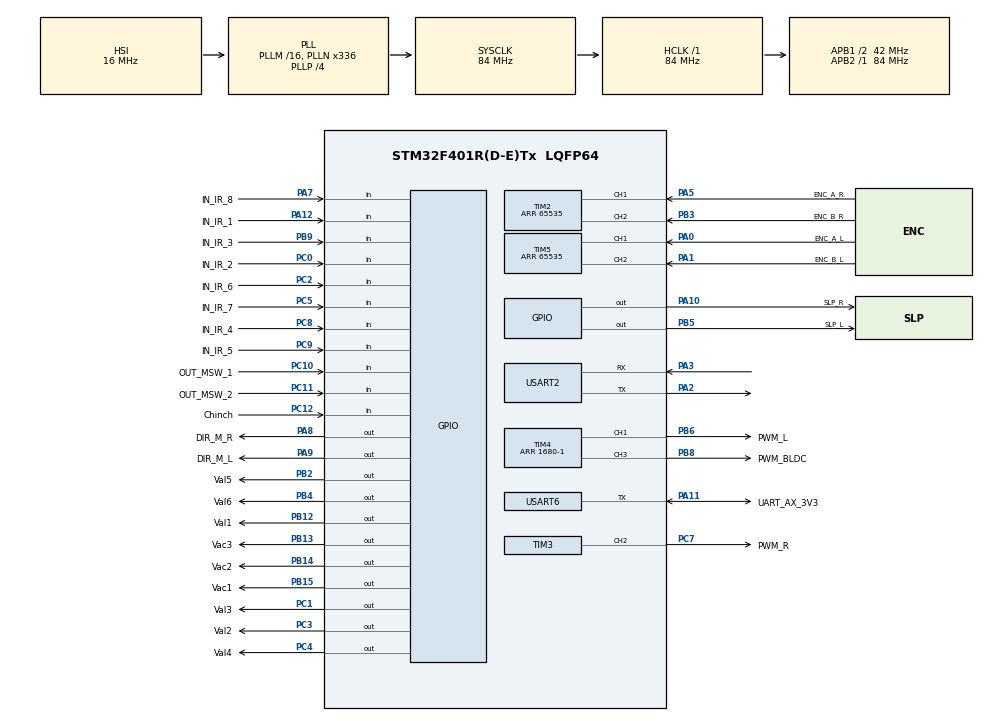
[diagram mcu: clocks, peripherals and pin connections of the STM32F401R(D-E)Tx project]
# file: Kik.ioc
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Mcu.Family=STM32F4
Mcu.Name=STM32F401R(D-E)Tx
Mcu.Package=LQFP64
NVIC.PriorityGroup=NVIC_PRIORITYGROUP_4
NVIC.TIM1_UP_TIM10_IRQn=true\:0\:0\:false\:false\:true\:true\:true\:true
PA0-WKUP.GPIO_Label=ENC_A_L
PA0-WKUP.Signal=S_TIM5_CH1
PA1.GPIO_Label=ENC_B_L
PA1.Signal=S_TIM5_CH2
PA10.GPIO_Label=SLP_R
PA10.PinState=GPIO_PIN_SET
PA10.Signal=GPIO_Output
PA11.GPIO_Label=UART_AX_3V3
PA11.GPIO_PuPd=GPIO_PULLUP
PA11.Mode=Half_duplex(single_wire_mode)
PA11.Signal=USART6_TX
PA12.GPIO_Label=IN_IR_1
PA12.Signal=GPIO_Input
PA2.Mode=Asynchronous
PA2.Signal=USART2_TX
PA3.Mode=Asynchronous
PA3.Signal=USART2_RX
PA5.GPIO_Label=ENC_A_R
PA5.Signal=S_TIM2_CH1_ETR
PA7.GPIO_Label=IN_IR_8
PA7.Signal=GPIO_Input
PA8.GPIO_Label=DIR_M_R
PA8.Signal=GPIO_Output
PA9.GPIO_Label=DIR_M_L
PA9.Signal=GPIO_Output
PB12.GPIO_Label=Val1
PB12.Signal=GPIO_Output
PB13.GPIO_Label=Vac3
PB13.Signal=GPIO_Output
PB14.GPIO_Label=Vac2
PB14.Signal=GPIO_Output
PB15.GPIO_Label=Vac1
PB15.Signal=GPIO_Output
PB2.GPIO_Label=Val5
PB2.Signal=GPIO_Output
PB3.GPIO_Label=ENC_B_R
PB3.Signal=S_TIM2_CH2
PB4.GPIO_Label=Val6
PB4.Signal=GPIO_Output
PB5.GPIO_Label=SLP_L
PB5.PinState=GPIO_PIN_SET
PB5.Signal=GPIO_Output
PB6.GPIO_Label=PWM_L
PB6.Signal=S_TIM4_CH1
PB8.GPIO_Label=PWM_BLDC
PB8.Signal=S_TIM4_CH3
PB9.GPIO_Label=IN_IR_3
PB9.Signal=GPIO_Input
PC0.GPIO_Label=IN_IR_2
PC0.Signal=GPIO_Input
PC1.GPIO_Label=Val3
PC1.Signal=GPIO_Output
PC10.GPIO_Label=OUT_MSW_1
PC10.Signal=GPIO_Input
PC11.GPIO_Label=OUT_MSW_2
PC11.Signal=GPIO_Input
PC12.GPIO_Label=Chinch
PC12.GPIO_PuPd=GPIO_PULLDOWN
PC12.Signal=GPIO_Input
PC2.GPIO_Label=IN_IR_6
PC2.Signal=GPIO_Input
PC3.GPIO_Label=Val2
PC3.Signal=GPIO_Output
PC4.GPIO_Label=Val4
PC4.Signal=GPIO_Output
PC5.GPIO_Label=IN_IR_7
PC5.Signal=GPIO_Input
PC7.GPIO_Label=PWM_R
PC7.Signal=S_TIM3_CH2
PC8.GPIO_Label=IN_IR_4
PC8.Signal=GPIO_Input
PC9.GPIO_Label=IN_IR_5
PC9.Signal=GPIO_Input
ProjectManager.HeapSize=0x200
ProjectManager.StackSize=0x400
ProjectManager.TargetToolchain=STM32CubeIDE
RCC.48MHZClocksFreq_Value=48000000
RCC.AHBFreq_Value=84000000
RCC.APB1CLKDivider=RCC_HCLK_DIV2
RCC.APB1Freq_Value=42000000
RCC.APB1TimFreq_Value=84000000
RCC.APB2Freq_Value=84000000
RCC.APB2TimFreq_Value=84000000
RCC.CortexFreq_Value=84000000
RCC.HCLKFreq_Value=84000000
RCC.HSE_VALUE=8000000
RCC.HSI_VALUE=16000000
RCC.LSE_VALUE=32768
RCC.PLLN=336
RCC.PLLP=RCC_PLLP_DIV4
RCC.PLLQ=7
RCC.SYSCLKFreq_VALUE=84000000
RCC.SYSCLKSource=RCC_SYSCLKSOURCE_PLLCLK
RCC.VCOOutputFreq_Value=336000000
SH.S_TIM2_CH1_ETR.0=TIM2_CH1,Encoder_Interface
SH.S_TIM2_CH2.0=TIM2_CH2,Encoder_Interface
SH.S_TIM3_CH2.0=TIM3_CH2,PWM Generation2 CH2
SH.S_TIM4_CH1.0=TIM4_CH1,PWM Generation1 CH1
SH.S_TIM4_CH3.0=TIM4_CH3,PWM Generation3 CH3
SH.S_TIM5_CH1.0=TIM5_CH1,Encoder_Interface
SH.S_TIM5_CH2.0=TIM5_CH2,Encoder_Interface
TIM10.Period=1000-1
TIM10.Prescaler=84-1
TIM2.EncoderMode=TIM_ENCODERMODE_TI12
TIM2.Period=65535
TIM3.AutoReloadPreload=TIM_AUTORELOAD_PRELOAD_ENABLE
TIM3.Channel-PWM\ Generation2\ CH2=TIM_CHANNEL_2
TIM3.Period=1680-1
TIM4.AutoReloadPreload=TIM_AUTORELOAD_PRELOAD_ENABLE
TIM4.Channel-PWM\ Generation1\ CH1=TIM_CHANNEL_1
TIM4.Channel-PWM\ Generation3\ CH3=TIM_CHANNEL_3
TIM4.Period=1680-1
TIM5.EncoderMode=TIM_ENCODERMODE_TI12
TIM5.Period=65535
USART2.VirtualMode=VM_ASYNC
USART6.BaudRate=57600
USART6.VirtualMode=VM_ASYNC
VP_TIM10_VS_ClockSourceINT.Mode=Enable_Timer
VP_TIM3_VS_ClockSourceINT.Mode=Internal
VP_TIM4_VS_ClockSourceINT.Mode=Internal
board=NUCLEO-F401RE

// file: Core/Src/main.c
/* USER CODE BEGIN Header */
/**
 ******************************************************************************
 * @file           : main.c
 * @brief          : Main program body
 ******************************************************************************
 * @attention
 *
 * Copyright (c) 2026 STMicroelectronics.
 * All rights reserved.
 *
 * This software is licensed under terms that can be found in the LICENSE file
 * in the root directory of this software component.
 * If no LICENSE file comes with this software, it is provided AS-IS.
 *
 ******************************************************************************
 */
/* USER CODE END Header */
#include "main.h"
#include "tim.h"
#include "usart.h"
#include "gpio.h"

void SystemClock_Config(void);

int main(void)
{

  /* MCU Configuration--------------------------------------------------------*/

  /* Reset of all peripherals, Initializes the Flash interface and the Systick. */
  HAL_Init();

  /* Configure the system clock */
  SystemClock_Config();

  /* Initialize all configured peripherals */
  MX_GPIO_Init();
  MX_TIM10_Init();
  MX_TIM2_Init();
  MX_TIM5_Init();
  MX_USART6_UART_Init();
  MX_TIM4_Init();
  MX_TIM3_Init();
  MX_USART2_UART_Init();
  /* USER CODE BEGIN 2 */
	time_start();
	encoder_init();
	pwm_init();
	ax_init ();
	pneumatika_init();
	//comm_init();      // ESP na USART1; bez ESP-a Nucleo radi isto kao ranije
	//watchdog_init();  // poslednje, posle sporih inicijalizacija

  /* USER CODE END 2 */

  /* Infinite loop */
	while (1) {

    /* USER CODE BEGIN 3 */

		//comm_poll();
		//watchdog_feed();
		//motori_set(100, -100);
	}
  /* USER CODE END 3 */
}

void SystemClock_Config(void)
{
  RCC_OscInitTypeDef RCC_OscInitStruct = {0};
  RCC_ClkInitTypeDef RCC_ClkInitStruct = {0};

  /** Configure the main internal regulator output voltage
  */
  __HAL_RCC_PWR_CLK_ENABLE();
  __HAL_PWR_VOLTAGESCALING_CONFIG(PWR_REGULATOR_VOLTAGE_SCALE2);

  /** Initializes the RCC Oscillators according to the specified parameters
  * in the RCC_OscInitTypeDef structure.
  */
  RCC_OscInitStruct.OscillatorType = RCC_OSCILLATORTYPE_HSI;
  RCC_OscInitStruct.HSIState = RCC_HSI_ON;
  RCC_OscInitStruct.HSICalibrationValue = RCC_HSICALIBRATION_DEFAULT;
  RCC_OscInitStruct.PLL.PLLState = RCC_PLL_ON;
  RCC_OscInitStruct.PLL.PLLSource = RCC_PLLSOURCE_HSI;
  RCC_OscInitStruct.PLL.PLLM = 16;
  RCC_OscInitStruct.PLL.PLLN = 336;
  RCC_OscInitStruct.PLL.PLLP = RCC_PLLP_DIV4;
  RCC_OscInitStruct.PLL.PLLQ = 7;
  if (HAL_RCC_OscConfig(&RCC_OscInitStruct) != HAL_OK)
  {
    Error_Handler();
  }

  /** Initializes the CPU, AHB and APB buses clocks
  */
  RCC_ClkInitStruct.ClockType = RCC_CLOCKTYPE_HCLK|RCC_CLOCKTYPE_SYSCLK
                              |RCC_CLOCKTYPE_PCLK1|RCC_CLOCKTYPE_PCLK2;
  RCC_ClkInitStruct.SYSCLKSource = RCC_SYSCLKSOURCE_PLLCLK;
  RCC_ClkInitStruct.AHBCLKDivider = RCC_SYSCLK_DIV1;
  RCC_ClkInitStruct.APB1CLKDivider = RCC_HCLK_DIV2;
  RCC_ClkInitStruct.APB2CLKDivider = RCC_HCLK_DIV1;

  if (HAL_RCC_ClockConfig(&RCC_ClkInitStruct, FLASH_LATENCY_2) != HAL_OK)
  {
    Error_Handler();
  }
}

void Error_Handler(void)
{
	__disable_irq();
	while (1) {
	}
}
#ifdef USE_FULL_ASSERT
/**
  * @brief  Reports the name of the source file and the source line number
  *         where the assert_param error has occurred.
  * @param  file: pointer to the source file name
  * @param  line: assert_param error line source number
  * @retval None
  */
void assert_failed(uint8_t *file, uint32_t line)
{
  /* USER CODE BEGIN 6 */

    /* User can add his own implementation to report the file name
       and the source line number, ex:
       printf("Wrong parameters value: file %s on line %d\r\n", file, line) */

  /* USER CODE END 6 */
}
#endif /* USE_FULL_ASSERT */
